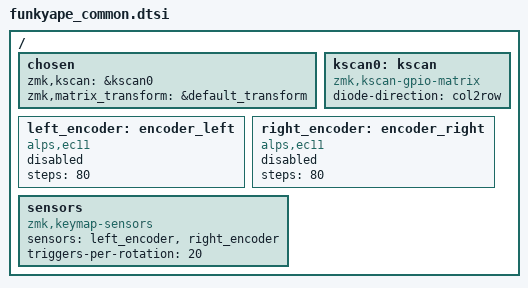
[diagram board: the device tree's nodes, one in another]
#include <dt-bindings/zmk/matrix_transform.h>

/ {
    chosen {
        zmk,kscan = &kscan0;
        zmk,matrix_transform = &default_transform;
    };

    kscan0: kscan {
        compatible = "zmk,kscan-gpio-matrix";
        diode-direction = "col2row";
    };

    left_encoder: encoder_left {
        compatible = "alps,ec11";
        steps = <80>;
        status = "disabled";
    };

    right_encoder: encoder_right {
        compatible = "alps,ec11";
        steps = <80>;
        status = "disabled";
    };

    sensors: sensors {
        compatible = "zmk,keymap-sensors";
        sensors = <&left_encoder &right_encoder>;
        triggers-per-rotation = <20>;
    };
};
